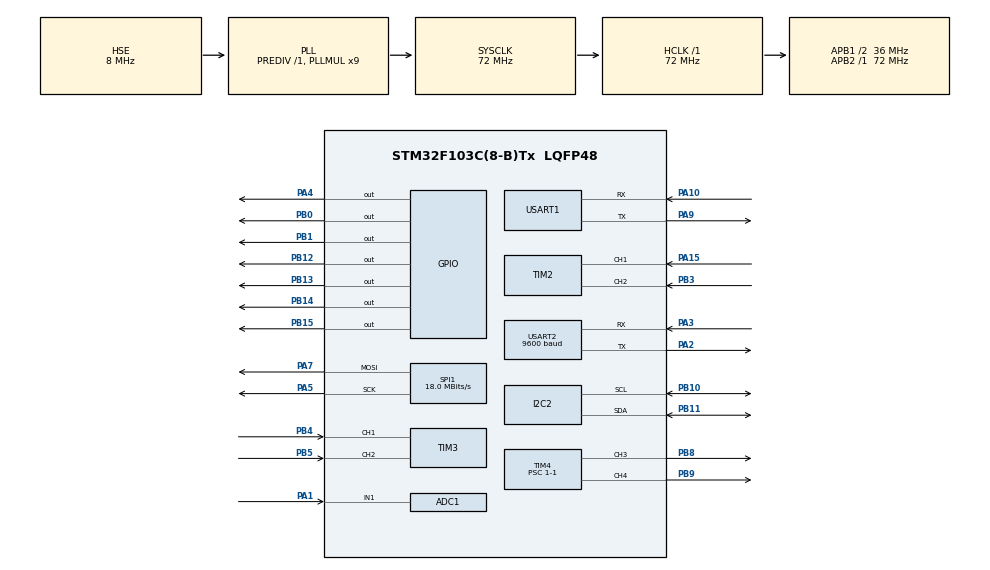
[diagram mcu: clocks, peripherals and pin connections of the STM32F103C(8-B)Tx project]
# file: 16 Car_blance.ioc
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ADC1.Channel-0\#ChannelRegularConversion=ADC_CHANNEL_1
ADC1.NbrOfConversion=1
ADC1.NbrOfConversionFlag=1
ADC1.Rank-0\#ChannelRegularConversion=1
ADC1.SamplingTime-0\#ChannelRegularConversion=ADC_SAMPLETIME_239CYCLES_5
ADC1.master=1
I2C2.I2C_Mode=I2C_Fast
Mcu.Family=STM32F1
Mcu.Name=STM32F103C(8-B)Tx
Mcu.Package=LQFP48
NVIC.PriorityGroup=NVIC_PRIORITYGROUP_4
NVIC.TIM1_UP_IRQn=true\:15\:0\:false\:false\:true\:false\:true\:true
NVIC.TimeBase=TIM1_UP_IRQn
NVIC.TimeBaseIP=TIM1
NVIC.USART1_IRQn=true\:0\:0\:false\:false\:true\:true\:true\:true
NVIC.USART2_IRQn=true\:0\:0\:false\:false\:true\:true\:true\:true
PA1.Signal=ADCx_IN1
PA10.Mode=Asynchronous
PA10.Signal=USART1_RX
PA13.Mode=Serial_Wire
PA13.Signal=SYS_JTMS-SWDIO
PA14.Mode=Serial_Wire
PA14.Signal=SYS_JTCK-SWCLK
PA15.Signal=S_TIM2_CH1_ETR
PA2.Mode=Asynchronous
PA2.Signal=USART2_TX
PA3.Mode=Asynchronous
PA3.Signal=USART2_RX
PA4.GPIO_Speed=GPIO_SPEED_FREQ_HIGH
PA4.PinState=GPIO_PIN_SET
PA4.Signal=GPIO_Output
PA5.Mode=TX_Only_Simplex_Unidirect_Master
PA5.Signal=SPI1_SCK
PA6.Signal=SPI1_MISO
PA7.Mode=TX_Only_Simplex_Unidirect_Master
PA7.Signal=SPI1_MOSI
PA9.Mode=Asynchronous
PA9.Signal=USART1_TX
PB0.GPIO_Speed=GPIO_SPEED_FREQ_HIGH
PB0.PinState=GPIO_PIN_SET
PB0.Signal=GPIO_Output
PB1.GPIO_Speed=GPIO_SPEED_FREQ_HIGH
PB1.PinState=GPIO_PIN_SET
PB1.Signal=GPIO_Output
PB10.Mode=I2C
PB10.Signal=I2C2_SCL
PB11.Mode=I2C
PB11.Signal=I2C2_SDA
PB12.Signal=GPIO_Output
PB13.Signal=GPIO_Output
PB14.Signal=GPIO_Output
PB15.Signal=GPIO_Output
PB3.Signal=S_TIM2_CH2
PB4.Signal=S_TIM3_CH1
PB5.Signal=S_TIM3_CH2
PB8.Signal=S_TIM4_CH3
PB9.Signal=S_TIM4_CH4
PC14-OSC32_IN.Mode=LSE-External-Oscillator
PC14-OSC32_IN.Signal=RCC_OSC32_IN
PC15-OSC32_OUT.Mode=LSE-External-Oscillator
PC15-OSC32_OUT.Signal=RCC_OSC32_OUT
PD0-OSC_IN.Mode=HSE-External-Oscillator
PD0-OSC_IN.Signal=RCC_OSC_IN
PD1-OSC_OUT.Mode=HSE-External-Oscillator
PD1-OSC_OUT.Signal=RCC_OSC_OUT
ProjectManager.HeapSize=0x200
ProjectManager.StackSize=0x400
ProjectManager.TargetToolchain=MDK-ARM V5.32
RCC.ADCPresc=RCC_ADCPCLK2_DIV6
RCC.AHBFreq_Value=72000000
RCC.APB1CLKDivider=RCC_HCLK_DIV2
RCC.APB1Freq_Value=36000000
RCC.APB1TimFreq_Value=72000000
RCC.APB2Freq_Value=72000000
RCC.APB2TimFreq_Value=72000000
RCC.HCLKFreq_Value=72000000
RCC.PLLMUL=RCC_PLL_MUL9
RCC.PLLSourceVirtual=RCC_PLLSOURCE_HSE
RCC.SYSCLKFreq_VALUE=72000000
RCC.SYSCLKSource=RCC_SYSCLKSOURCE_PLLCLK
RCC.USBFreq_Value=72000000
SH.ADCx_IN1.0=ADC1_IN1,IN1
SH.S_TIM2_CH1_ETR.0=TIM2_CH1,Encoder_Interface
SH.S_TIM2_CH2.0=TIM2_CH2,Encoder_Interface
SH.S_TIM3_CH1.0=TIM3_CH1,Encoder_Interface
SH.S_TIM3_CH2.0=TIM3_CH2,Encoder_Interface
SH.S_TIM4_CH3.0=TIM4_CH3,PWM Generation3 CH3
SH.S_TIM4_CH4.0=TIM4_CH4,PWM Generation4 CH4
SPI1.BaudRatePrescaler=SPI_BAUDRATEPRESCALER_4
SPI1.CalculateBaudRate=18.0 MBits/s
SPI1.Direction=SPI_DIRECTION_2LINES
SPI1.Mode=SPI_MODE_MASTER
SPI1.VirtualType=VM_MASTER
TIM4.Channel-PWM\ Generation3\ CH3=TIM_CHANNEL_3
TIM4.Channel-PWM\ Generation4\ CH4=TIM_CHANNEL_4
TIM4.Period=7199
TIM4.Prescaler=1-1
USART1.VirtualMode=VM_ASYNC
USART2.BaudRate=9600
USART2.VirtualMode=VM_ASYNC
VP_SYS_VS_tim1.Mode=TIM1
VP_TIM4_VS_ClockSourceINT.Mode=Internal
board=custom

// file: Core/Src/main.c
/* USER CODE BEGIN Header */
/**
  ******************************************************************************
  * @file           : main.c
  * @brief          : Main program body
  ******************************************************************************
  * @attention
  *
  * Copyright (c) 2025 STMicroelectronics.
  * All rights reserved.
  *
  * This software is licensed under terms that can be found in the LICENSE file
  * in the root directory of this software component.
  * If no LICENSE file comes with this software, it is provided AS-IS.
  *
  ******************************************************************************
  */
/* USER CODE END Header */
#include "main.h"
#include "adc.h"
#include "i2c.h"
#include "spi.h"
#include "tim.h"
#include "usart.h"
#include "gpio.h"

/* USER CODE BEGIN Includes */
#include "MPU6050.h"
#include "App_Car.h"
#include "oled.h"
/* USER CODE END Includes */

void SystemClock_Config(void);

int main(void)
{

  /* MCU Configuration--------------------------------------------------------*/

  /* Reset of all peripherals, Initializes the Flash interface and the Systick. */
  HAL_Init();

  /* Configure the system clock */
  SystemClock_Config();

  /* Initialize all configured peripherals */
  MX_GPIO_Init();
  MX_TIM4_Init();
  MX_ADC1_Init();
  MX_I2C2_Init();
  MX_SPI1_Init();
  MX_TIM2_Init();
  MX_TIM3_Init();
  MX_USART1_UART_Init();
  MX_USART2_UART_Init();
  /* USER CODE BEGIN 2 */

  MPU6050_Init();
  MPU6050_Sample_Rate(100);

  HAL_ADCEx_Calibration_Start(&hadc1);
  HAL_ADC_Start(&hadc1);
  OLED_Init();

  OLED_Clear();
  /* USER CODE END 2 */

  /* Infinite loop */
  /* USER CODE BEGIN WHILE */
  while (1)
  {
    Get_Kalman_Angle();
    Show_Informain();

    /* USER CODE END WHILE */

  }
}

void SystemClock_Config(void)
{
  RCC_OscInitTypeDef RCC_OscInitStruct = {0};
  RCC_ClkInitTypeDef RCC_ClkInitStruct = {0};
  RCC_PeriphCLKInitTypeDef PeriphClkInit = {0};

  /** Initializes the RCC Oscillators according to the specified parameters
  * in the RCC_OscInitTypeDef structure.
  */
  RCC_OscInitStruct.OscillatorType = RCC_OSCILLATORTYPE_HSE;
  RCC_OscInitStruct.HSEState = RCC_HSE_ON;
  RCC_OscInitStruct.HSEPredivValue = RCC_HSE_PREDIV_DIV1;
  RCC_OscInitStruct.HSIState = RCC_HSI_ON;
  RCC_OscInitStruct.PLL.PLLState = RCC_PLL_ON;
  RCC_OscInitStruct.PLL.PLLSource = RCC_PLLSOURCE_HSE;
  RCC_OscInitStruct.PLL.PLLMUL = RCC_PLL_MUL9;
  if (HAL_RCC_OscConfig(&RCC_OscInitStruct) != HAL_OK)
  {
    Error_Handler();
  }

  /** Initializes the CPU, AHB and APB buses clocks
  */
  RCC_ClkInitStruct.ClockType = RCC_CLOCKTYPE_HCLK|RCC_CLOCKTYPE_SYSCLK
                              |RCC_CLOCKTYPE_PCLK1|RCC_CLOCKTYPE_PCLK2;
  RCC_ClkInitStruct.SYSCLKSource = RCC_SYSCLKSOURCE_PLLCLK;
  RCC_ClkInitStruct.AHBCLKDivider = RCC_SYSCLK_DIV1;
  RCC_ClkInitStruct.APB1CLKDivider = RCC_HCLK_DIV2;
  RCC_ClkInitStruct.APB2CLKDivider = RCC_HCLK_DIV1;

  if (HAL_RCC_ClockConfig(&RCC_ClkInitStruct, FLASH_LATENCY_2) != HAL_OK)
  {
    Error_Handler();
  }
  PeriphClkInit.PeriphClockSelection = RCC_PERIPHCLK_ADC;
  PeriphClkInit.AdcClockSelection = RCC_ADCPCLK2_DIV6;
  if (HAL_RCCEx_PeriphCLKConfig(&PeriphClkInit) != HAL_OK)
  {
    Error_Handler();
  }
}

void HAL_TIM_PeriodElapsedCallback(TIM_HandleTypeDef *htim)
{
  if (htim->Instance == TIM1)
  {
    HAL_IncTick();
  }
}

void Error_Handler(void)
{
  __disable_irq();
  while (1)
  {
  }
}
